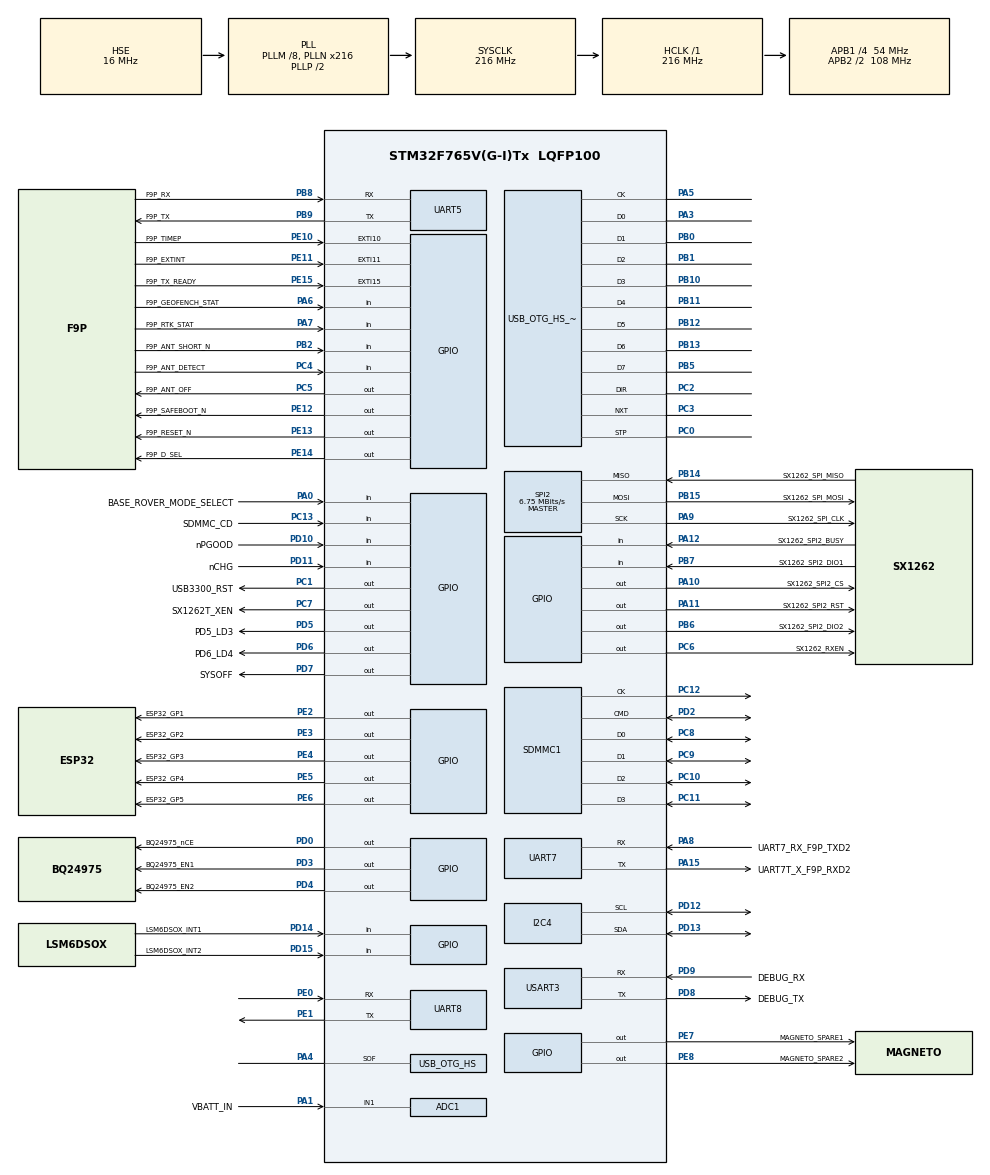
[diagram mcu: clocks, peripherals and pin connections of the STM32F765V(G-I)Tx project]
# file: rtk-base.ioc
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ADC1.Channel-1\#ChannelRegularConversion=ADC_CHANNEL_1
ADC1.NbrOfConversionFlag=1
ADC1.Rank-1\#ChannelRegularConversion=1
ADC1.SamplingTime-1\#ChannelRegularConversion=ADC_SAMPLETIME_3CYCLES
ADC1.master=1
CORTEX_M7.default_mode_Activation=1
FREERTOS.Tasks01=defaultTask,24,256,StartDefaultTask,Default,NULL,Dynamic,NULL,NULL
FREERTOS.configUSE_NEWLIB_REENTRANT=1
I2C4.Timing=0x20404768
Mcu.Family=STM32F7
Mcu.Name=STM32F765V(G-I)Tx
Mcu.Package=LQFP100
NVIC.OTG_HS_EP1_IN_IRQn=true\:5\:0\:false\:false\:true\:true\:true\:true\:true
NVIC.OTG_HS_EP1_OUT_IRQn=true\:5\:0\:false\:false\:true\:true\:true\:true\:true
NVIC.OTG_HS_IRQn=true\:5\:0\:false\:false\:true\:true\:true\:true\:true
NVIC.PriorityGroup=NVIC_PRIORITYGROUP_4
NVIC.TIM6_DAC_IRQn=true\:15\:0\:false\:false\:true\:false\:false\:true\:true
NVIC.TimeBase=TIM6_DAC_IRQn
NVIC.TimeBaseIP=TIM6
PA0/WKUP.GPIO_Label=BASE_ROVER_MODE_SELECT
PA0/WKUP.GPIO_PuPd=GPIO_PULLUP
PA0/WKUP.Signal=GPIO_Input
PA1.GPIO_Label=VBATT_IN
PA1.Signal=ADCx_IN1
PA10.GPIO_Label=SX1262_SPI2_CS
PA10.PinState=GPIO_PIN_SET
PA10.Signal=GPIO_Output
PA11.GPIO_Label=SX1262_SPI2_RST
PA11.Signal=GPIO_Output
PA12.GPIO_Label=SX1262_SPI2_BUSY
PA12.GPIO_PuPd=GPIO_PULLUP
PA12.Signal=GPIO_Input
PA13.Mode=Serial_Wire
PA13.Signal=SYS_JTMS-SWDIO
PA14.Mode=Serial_Wire
PA14.Signal=SYS_JTCK-SWCLK
PA15.GPIO_Label=UART7T_X_F9P_RXD2
PA15.Mode=Asynchronous
PA15.Signal=UART7_TX
PA3.Mode=Device_HS
PA3.Signal=USB_OTG_HS_ULPI_D0
PA4.Mode=Activate_SOF_FS
PA4.Signal=USB_OTG_HS_SOF
PA5.Mode=Device_HS
PA5.Signal=USB_OTG_HS_ULPI_CK
PA6.GPIO_Label=F9P_GEOFENCH_STAT
PA6.Signal=GPIO_Input
PA7.GPIO_Label=F9P_RTK_STAT
PA7.Signal=GPIO_Input
PA8.GPIO_Label=UART7_RX_F9P_TXD2
PA8.Mode=Asynchronous
PA8.Signal=UART7_RX
PA9.GPIO_Label=SX1262_SPI_CLK
PA9.Mode=Full_Duplex_Master
PA9.Signal=SPI2_SCK
PB0.Mode=Device_HS
PB0.Signal=USB_OTG_HS_ULPI_D1
PB1.Mode=Device_HS
PB1.Signal=USB_OTG_HS_ULPI_D2
PB10.Mode=Device_HS
PB10.Signal=USB_OTG_HS_ULPI_D3
PB11.Mode=Device_HS
PB11.Signal=USB_OTG_HS_ULPI_D4
PB12.Mode=Device_HS
PB12.Signal=USB_OTG_HS_ULPI_D5
PB13.Mode=Device_HS
PB13.Signal=USB_OTG_HS_ULPI_D6
PB14.GPIO_Label=SX1262_SPI_MISO
PB14.Mode=Full_Duplex_Master
PB14.Signal=SPI2_MISO
PB15.GPIO_Label=SX1262_SPI_MOSI
PB15.Mode=Full_Duplex_Master
PB15.Signal=SPI2_MOSI
PB2.GPIO_Label=F9P_ANT_SHORT_N
PB2.Signal=GPIO_Input
PB3.Signal=SYS_JTDO-SWO
PB5.Mode=Device_HS
PB5.Signal=USB_OTG_HS_ULPI_D7
PB6.GPIO_Label=SX1262_SPI2_DIO2
PB6.Signal=GPIO_Output
PB7.GPIO_Label=SX1262_SPI2_DIO1
PB7.Signal=GPIO_Input
PB8.GPIO_Label=F9P_RX
PB8.Mode=Asynchronous
PB8.Signal=UART5_RX
PB9.GPIO_Label=F9P_TX
PB9.Mode=Asynchronous
PB9.Signal=UART5_TX
PC0.Mode=Device_HS
PC0.Signal=USB_OTG_HS_ULPI_STP
PC1.GPIO_Label=USB3300_RST
PC1.GPIO_Speed=GPIO_SPEED_FREQ_HIGH
PC1.Signal=GPIO_Output
PC10.Mode=SD_4_bits_Wide_bus
PC10.Signal=SDMMC1_D2
PC11.Mode=SD_4_bits_Wide_bus
PC11.Signal=SDMMC1_D3
PC12.Mode=SD_4_bits_Wide_bus
PC12.Signal=SDMMC1_CK
PC13.GPIO_Label=SDMMC_CD
PC13.GPIO_PuPd=GPIO_PULLUP
PC13.Signal=GPIO_Input
PC2.Mode=Device_HS
PC2.Signal=USB_OTG_HS_ULPI_DIR
PC3.Mode=Device_HS
PC3.Signal=USB_OTG_HS_ULPI_NXT
PC4.GPIO_Label=F9P_ANT_DETECT
PC4.Signal=GPIO_Input
PC5.GPIO_Label=F9P_ANT_OFF
PC5.Signal=GPIO_Output
PC6.GPIO_Label=SX1262_RXEN
PC6.Signal=GPIO_Output
PC7.GPIO_Label=SX1262T_XEN
PC7.Signal=GPIO_Output
PC8.Mode=SD_4_bits_Wide_bus
PC8.Signal=SDMMC1_D0
PC9.Mode=SD_4_bits_Wide_bus
PC9.Signal=SDMMC1_D1
PD0.GPIO_Label=BQ24975_nCE
PD0.Signal=GPIO_Output
PD10.GPIO_Label=nPGOOD
PD10.Signal=GPIO_Input
PD11.GPIO_Label=nCHG
PD11.Signal=GPIO_Input
PD12.Mode=I2C
PD12.Signal=I2C4_SCL
PD13.Mode=I2C
PD13.Signal=I2C4_SDA
PD14.GPIO_Label=LSM6DSOX_INT1
PD14.Signal=GPIO_Input
PD15.GPIO_Label=LSM6DSOX_INT2
PD15.Signal=GPIO_Input
PD2.Mode=SD_4_bits_Wide_bus
PD2.Signal=SDMMC1_CMD
PD3.GPIO_Label=BQ24975_EN1
PD3.PinState=GPIO_PIN_SET
PD3.Signal=GPIO_Output
PD4.GPIO_Label=BQ24975_EN2
PD4.PinState=GPIO_PIN_RESET
PD4.Signal=GPIO_Output
PD5.GPIO_Label=PD5_LD3
PD5.GPIO_ModeDefaultOutputPP=GPIO_MODE_OUTPUT_OD
PD5.GPIO_PuPd=GPIO_NOPULL
PD5.Signal=GPIO_Output
PD6.GPIO_Label=PD6_LD4
PD6.GPIO_ModeDefaultOutputPP=GPIO_MODE_OUTPUT_OD
PD6.GPIO_PuPd=GPIO_NOPULL
PD6.Signal=GPIO_Output
PD7.GPIO_Label=SYSOFF
PD7.Signal=GPIO_Output
PD8.GPIO_Label=DEBUG_TX
PD8.Mode=Asynchronous
PD8.Signal=USART3_TX
PD9.GPIO_Label=DEBUG_RX
PD9.Mode=Asynchronous
PD9.Signal=USART3_RX
PE0.Mode=Asynchronous
PE0.Signal=UART8_RX
PE1.Mode=Asynchronous
PE1.Signal=UART8_TX
PE10.GPIO_Label=F9P_TIMEP
PE10.Signal=GPXTI10
PE11.GPIO_Label=F9P_EXTINT
PE11.Signal=GPXTI11
PE12.GPIO_Label=F9P_SAFEBOOT_N
PE12.PinState=GPIO_PIN_SET
PE12.Signal=GPIO_Output
PE13.GPIO_Label=F9P_RESET_N
PE13.PinState=GPIO_PIN_SET
PE13.Signal=GPIO_Output
PE14.GPIO_Label=F9P_D_SEL
PE14.PinState=GPIO_PIN_SET
PE14.Signal=GPIO_Output
PE15.GPIO_Label=F9P_TX_READY
PE15.Signal=GPXTI15
PE2.GPIO_Label=ESP32_GP1
PE2.Signal=GPIO_Output
PE3.GPIO_Label=ESP32_GP2
PE3.Signal=GPIO_Output
PE4.GPIO_Label=ESP32_GP3
PE4.Signal=GPIO_Output
PE5.GPIO_Label=ESP32_GP4
PE5.Signal=GPIO_Output
PE6.GPIO_Label=ESP32_GP5
PE6.Signal=GPIO_Output
PE7.GPIO_Label=MAGNETO_SPARE1
PE7.Signal=GPIO_Output
PE8.GPIO_Label=MAGNETO_SPARE2
PE8.Signal=GPIO_Output
PH0/OSC_IN.Mode=HSE-External-Oscillator
PH0/OSC_IN.Signal=RCC_OSC_IN
PH1/OSC_OUT.Mode=HSE-External-Oscillator
PH1/OSC_OUT.Signal=RCC_OSC_OUT
ProjectManager.HeapSize=0x200
ProjectManager.StackSize=0x400
ProjectManager.TargetToolchain=STM32CubeIDE
RCC.AHBFreq_Value=216000000
RCC.APB1CLKDivider=RCC_HCLK_DIV4
RCC.APB1Freq_Value=54000000
RCC.APB1TimFreq_Value=108000000
RCC.APB2CLKDivider=RCC_HCLK_DIV2
RCC.APB2Freq_Value=108000000
RCC.APB2TimFreq_Value=216000000
RCC.CortexFreq_Value=216000000
RCC.HCLKFreq_Value=216000000
RCC.HSE_VALUE=16000000
RCC.HSI_VALUE=16000000
RCC.LSE_VALUE=32768
RCC.PLLM=8
RCC.PLLN=216
RCC.PLLQ=9
RCC.PLLSourceVirtual=RCC_PLLSOURCE_HSE
RCC.SDMMCClockSelection=RCC_SDMMC1CLKSOURCE_CLK48
RCC.SYSCLKFreq_VALUE=216000000
RCC.SYSCLKSource=RCC_SYSCLKSOURCE_PLLCLK
RCC.USBFreq_Value=48000000
RCC.VCOOutputFreq_Value=432000000
SH.ADCx_IN1.0=ADC1_IN1,IN1
SPI2.BaudRatePrescaler=SPI_BAUDRATEPRESCALER_8
SPI2.CalculateBaudRate=6.75 MBits/s
SPI2.DataSize=SPI_DATASIZE_8BIT
SPI2.Direction=SPI_DIRECTION_2LINES
SPI2.Mode=SPI_MODE_MASTER
SPI2.VirtualType=VM_MASTER
USART3.VirtualMode-Asynchronous=VM_ASYNC
USB_OTG_HS.VirtualMode-Device_HS=Device_HS
VP_FREERTOS_VS_CMSIS_V2.Mode=CMSIS_V2
VP_SYS_VS_tim6.Mode=TIM6
board=custom

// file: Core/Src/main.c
/* USER CODE BEGIN Header */
/**
  ******************************************************************************
  * @file           : main.c
  * @brief          : Main program body
  ******************************************************************************
  * @attention
  *
  * Copyright (c) 2026 STMicroelectronics.
  * All rights reserved.
  *
  * This software is licensed under terms that can be found in the LICENSE file
  * in the root directory of this software component.
  * If no LICENSE file comes with this software, it is provided AS-IS.
  *
  ******************************************************************************
  */
/* USER CODE END Header */
#include "main.h"
#include "cmsis_os.h"

/* USER CODE BEGIN Includes */
#include "task_battery.h"
/* USER CODE END Includes */

ADC_HandleTypeDef hadc1;

I2C_HandleTypeDef hi2c4;

SD_HandleTypeDef hsd1;

SPI_HandleTypeDef hspi2;

UART_HandleTypeDef huart5;
UART_HandleTypeDef huart7;
UART_HandleTypeDef huart8;
UART_HandleTypeDef huart3;

PCD_HandleTypeDef hpcd_USB_OTG_HS;

/* Definitions for defaultTask */
osThreadId_t defaultTaskHandle;
const osThreadAttr_t defaultTask_attributes = {
  .name = "defaultTask",
  .stack_size = 256 * 4,
  .priority = (osPriority_t) osPriorityNormal,
};
/* USER CODE BEGIN PV */
osThreadId_t batteryTaskHandle;
const osThreadAttr_t batteryTask_attributes = {
	.name       = "batteryTask",
	.stack_size = 128 * 4,
	.priority   = (osPriority_t)osPriorityBelowNormal,
};
/* USER CODE END PV */

void SystemClock_Config(void);
static void MPU_Config(void);
static void MX_GPIO_Init(void);
static void MX_USART3_UART_Init(void);
static void MX_I2C4_Init(void);
static void MX_SDMMC1_SD_Init(void);
static void MX_SPI2_Init(void);
static void MX_UART5_Init(void);
static void MX_UART8_Init(void);
static void MX_USB_OTG_HS_PCD_Init(void);
static void MX_ADC1_Init(void);
static void MX_UART7_Init(void);
void StartDefaultTask(void *argument);

int main(void)
{

  /* MPU Configuration--------------------------------------------------------*/
  MPU_Config();

  /* MCU Configuration--------------------------------------------------------*/

  /* Reset of all peripherals, Initializes the Flash interface and the Systick. */
  HAL_Init();

  /* Configure the system clock */
  SystemClock_Config();

  /* Initialize all configured peripherals */
  MX_GPIO_Init();
  MX_USART3_UART_Init();
  MX_I2C4_Init();
  MX_SDMMC1_SD_Init();
  MX_SPI2_Init();
  MX_UART5_Init();
  MX_UART8_Init();
  MX_USB_OTG_HS_PCD_Init();
  MX_ADC1_Init();
  MX_UART7_Init();

  /* Init scheduler */
  osKernelInitialize();

  /* Create the thread(s) */
  /* creation of defaultTask */
  defaultTaskHandle = osThreadNew(StartDefaultTask, NULL, &defaultTask_attributes);

  /* USER CODE BEGIN RTOS_THREADS */
  batteryTaskHandle = osThreadNew(task_battery, NULL, &batteryTask_attributes);
  /* USER CODE END RTOS_THREADS */

  /* Start scheduler */
  osKernelStart();

  /* We should never get here as control is now taken by the scheduler */

  /* Infinite loop */
  while (1)
  {

  }
}

void SystemClock_Config(void)
{
  RCC_OscInitTypeDef RCC_OscInitStruct = {0};
  RCC_ClkInitTypeDef RCC_ClkInitStruct = {0};

  /** Configure the main internal regulator output voltage
  */
  __HAL_RCC_PWR_CLK_ENABLE();
  __HAL_PWR_VOLTAGESCALING_CONFIG(PWR_REGULATOR_VOLTAGE_SCALE1);

  /** Initializes the RCC Oscillators according to the specified parameters
  * in the RCC_OscInitTypeDef structure.
  */
  RCC_OscInitStruct.OscillatorType = RCC_OSCILLATORTYPE_HSE;
  RCC_OscInitStruct.HSEState = RCC_HSE_ON;
  RCC_OscInitStruct.PLL.PLLState = RCC_PLL_ON;
  RCC_OscInitStruct.PLL.PLLSource = RCC_PLLSOURCE_HSE;
  RCC_OscInitStruct.PLL.PLLM = 8;
  RCC_OscInitStruct.PLL.PLLN = 216;
  RCC_OscInitStruct.PLL.PLLP = RCC_PLLP_DIV2;
  RCC_OscInitStruct.PLL.PLLQ = 9;
  RCC_OscInitStruct.PLL.PLLR = 2;
  if (HAL_RCC_OscConfig(&RCC_OscInitStruct) != HAL_OK)
  {
    Error_Handler();
  }

  /** Activate the Over-Drive mode
  */
  if (HAL_PWREx_EnableOverDrive() != HAL_OK)
  {
    Error_Handler();
  }

  /** Initializes the CPU, AHB and APB buses clocks
  */
  RCC_ClkInitStruct.ClockType = RCC_CLOCKTYPE_HCLK|RCC_CLOCKTYPE_SYSCLK
                              |RCC_CLOCKTYPE_PCLK1|RCC_CLOCKTYPE_PCLK2;
  RCC_ClkInitStruct.SYSCLKSource = RCC_SYSCLKSOURCE_PLLCLK;
  RCC_ClkInitStruct.AHBCLKDivider = RCC_SYSCLK_DIV1;
  RCC_ClkInitStruct.APB1CLKDivider = RCC_HCLK_DIV4;
  RCC_ClkInitStruct.APB2CLKDivider = RCC_HCLK_DIV2;

  if (HAL_RCC_ClockConfig(&RCC_ClkInitStruct, FLASH_LATENCY_7) != HAL_OK)
  {
    Error_Handler();
  }
}

static void MX_ADC1_Init(void)
{

  ADC_ChannelConfTypeDef sConfig = {0};

  /** Configure the global features of the ADC (Clock, Resolution, Data Alignment and number of conversion)
  */
  hadc1.Instance = ADC1;
  hadc1.Init.ClockPrescaler = ADC_CLOCK_SYNC_PCLK_DIV4;
  hadc1.Init.Resolution = ADC_RESOLUTION_12B;
  hadc1.Init.ScanConvMode = ADC_SCAN_DISABLE;
  hadc1.Init.ContinuousConvMode = DISABLE;
  hadc1.Init.DiscontinuousConvMode = DISABLE;
  hadc1.Init.ExternalTrigConvEdge = ADC_EXTERNALTRIGCONVEDGE_NONE;
  hadc1.Init.ExternalTrigConv = ADC_SOFTWARE_START;
  hadc1.Init.DataAlign = ADC_DATAALIGN_RIGHT;
  hadc1.Init.NbrOfConversion = 1;
  hadc1.Init.DMAContinuousRequests = DISABLE;
  hadc1.Init.EOCSelection = ADC_EOC_SINGLE_CONV;
  if (HAL_ADC_Init(&hadc1) != HAL_OK)
  {
    Error_Handler();
  }

  /** Configure for the selected ADC regular channel its corresponding rank in the sequencer and its sample time.
  */
  sConfig.Channel = ADC_CHANNEL_1;
  sConfig.Rank = ADC_REGULAR_RANK_1;
  sConfig.SamplingTime = ADC_SAMPLETIME_3CYCLES;
  if (HAL_ADC_ConfigChannel(&hadc1, &sConfig) != HAL_OK)
  {
    Error_Handler();
  }

}

static void MX_I2C4_Init(void)
{

  hi2c4.Instance = I2C4;
  hi2c4.Init.Timing = 0x20404768;
  hi2c4.Init.OwnAddress1 = 0;
  hi2c4.Init.AddressingMode = I2C_ADDRESSINGMODE_7BIT;
  hi2c4.Init.DualAddressMode = I2C_DUALADDRESS_DISABLE;
  hi2c4.Init.OwnAddress2 = 0;
  hi2c4.Init.OwnAddress2Masks = I2C_OA2_NOMASK;
  hi2c4.Init.GeneralCallMode = I2C_GENERALCALL_DISABLE;
  hi2c4.Init.NoStretchMode = I2C_NOSTRETCH_DISABLE;
  if (HAL_I2C_Init(&hi2c4) != HAL_OK)
  {
    Error_Handler();
  }

  /** Configure Analogue filter
  */
  if (HAL_I2CEx_ConfigAnalogFilter(&hi2c4, I2C_ANALOGFILTER_ENABLE) != HAL_OK)
  {
    Error_Handler();
  }

  /** Configure Digital filter
  */
  if (HAL_I2CEx_ConfigDigitalFilter(&hi2c4, 0) != HAL_OK)
  {
    Error_Handler();
  }

}

static void MX_SDMMC1_SD_Init(void)
{

  hsd1.Instance = SDMMC1;
  hsd1.Init.ClockEdge = SDMMC_CLOCK_EDGE_RISING;
  hsd1.Init.ClockBypass = SDMMC_CLOCK_BYPASS_DISABLE;
  hsd1.Init.ClockPowerSave = SDMMC_CLOCK_POWER_SAVE_DISABLE;
  hsd1.Init.BusWide = SDMMC_BUS_WIDE_1B;
  hsd1.Init.HardwareFlowControl = SDMMC_HARDWARE_FLOW_CONTROL_DISABLE;
  hsd1.Init.ClockDiv = 0;
  if (HAL_SD_Init(&hsd1) != HAL_OK)
  {
    Error_Handler();
  }
  if (HAL_SD_ConfigWideBusOperation(&hsd1, SDMMC_BUS_WIDE_4B) != HAL_OK)
  {
    Error_Handler();
  }

}

static void MX_SPI2_Init(void)
{

  /* SPI2 parameter configuration*/
  hspi2.Instance = SPI2;
  hspi2.Init.Mode = SPI_MODE_MASTER;
  hspi2.Init.Direction = SPI_DIRECTION_2LINES;
  hspi2.Init.DataSize = SPI_DATASIZE_8BIT;
  hspi2.Init.CLKPolarity = SPI_POLARITY_LOW;
  hspi2.Init.CLKPhase = SPI_PHASE_1EDGE;
  hspi2.Init.NSS = SPI_NSS_SOFT;
  hspi2.Init.BaudRatePrescaler = SPI_BAUDRATEPRESCALER_8;
  hspi2.Init.FirstBit = SPI_FIRSTBIT_MSB;
  hspi2.Init.TIMode = SPI_TIMODE_DISABLE;
  hspi2.Init.CRCCalculation = SPI_CRCCALCULATION_DISABLE;
  hspi2.Init.CRCPolynomial = 7;
  hspi2.Init.CRCLength = SPI_CRC_LENGTH_DATASIZE;
  hspi2.Init.NSSPMode = SPI_NSS_PULSE_ENABLE;
  if (HAL_SPI_Init(&hspi2) != HAL_OK)
  {
    Error_Handler();
  }

}

static void MX_UART5_Init(void)
{

  huart5.Instance = UART5;
  huart5.Init.BaudRate = 115200;
  huart5.Init.WordLength = UART_WORDLENGTH_8B;
  huart5.Init.StopBits = UART_STOPBITS_1;
  huart5.Init.Parity = UART_PARITY_NONE;
  huart5.Init.Mode = UART_MODE_TX_RX;
  huart5.Init.HwFlowCtl = UART_HWCONTROL_NONE;
  huart5.Init.OverSampling = UART_OVERSAMPLING_16;
  huart5.Init.OneBitSampling = UART_ONE_BIT_SAMPLE_DISABLE;
  huart5.AdvancedInit.AdvFeatureInit = UART_ADVFEATURE_NO_INIT;
  if (HAL_UART_Init(&huart5) != HAL_OK)
  {
    Error_Handler();
  }

}

static void MX_UART7_Init(void)
{

  huart7.Instance = UART7;
  huart7.Init.BaudRate = 115200;
  huart7.Init.WordLength = UART_WORDLENGTH_8B;
  huart7.Init.StopBits = UART_STOPBITS_1;
  huart7.Init.Parity = UART_PARITY_NONE;
  huart7.Init.Mode = UART_MODE_TX_RX;
  huart7.Init.HwFlowCtl = UART_HWCONTROL_NONE;
  huart7.Init.OverSampling = UART_OVERSAMPLING_16;
  huart7.Init.OneBitSampling = UART_ONE_BIT_SAMPLE_DISABLE;
  huart7.AdvancedInit.AdvFeatureInit = UART_ADVFEATURE_NO_INIT;
  if (HAL_UART_Init(&huart7) != HAL_OK)
  {
    Error_Handler();
  }

}

static void MX_UART8_Init(void)
{

  huart8.Instance = UART8;
  huart8.Init.BaudRate = 115200;
  huart8.Init.WordLength = UART_WORDLENGTH_8B;
  huart8.Init.StopBits = UART_STOPBITS_1;
  huart8.Init.Parity = UART_PARITY_NONE;
  huart8.Init.Mode = UART_MODE_TX_RX;
  huart8.Init.HwFlowCtl = UART_HWCONTROL_NONE;
  huart8.Init.OverSampling = UART_OVERSAMPLING_16;
  huart8.Init.OneBitSampling = UART_ONE_BIT_SAMPLE_DISABLE;
  huart8.AdvancedInit.AdvFeatureInit = UART_ADVFEATURE_NO_INIT;
  if (HAL_UART_Init(&huart8) != HAL_OK)
  {
    Error_Handler();
  }

}

static void MX_USART3_UART_Init(void)
{

  huart3.Instance = USART3;
  huart3.Init.BaudRate = 115200;
  huart3.Init.WordLength = UART_WORDLENGTH_8B;
  huart3.Init.StopBits = UART_STOPBITS_1;
  huart3.Init.Parity = UART_PARITY_NONE;
  huart3.Init.Mode = UART_MODE_TX_RX;
  huart3.Init.HwFlowCtl = UART_HWCONTROL_NONE;
  huart3.Init.OverSampling = UART_OVERSAMPLING_16;
  huart3.Init.OneBitSampling = UART_ONE_BIT_SAMPLE_DISABLE;
  huart3.AdvancedInit.AdvFeatureInit = UART_ADVFEATURE_NO_INIT;
  if (HAL_UART_Init(&huart3) != HAL_OK)
  {
    Error_Handler();
  }

}

static void MX_USB_OTG_HS_PCD_Init(void)
{

  hpcd_USB_OTG_HS.Instance = USB_OTG_HS;
  hpcd_USB_OTG_HS.Init.dev_endpoints = 9;
  hpcd_USB_OTG_HS.Init.speed = PCD_SPEED_HIGH;
  hpcd_USB_OTG_HS.Init.dma_enable = DISABLE;
  hpcd_USB_OTG_HS.Init.phy_itface = USB_OTG_ULPI_PHY;
  hpcd_USB_OTG_HS.Init.Sof_enable = ENABLE;
  hpcd_USB_OTG_HS.Init.low_power_enable = DISABLE;
  hpcd_USB_OTG_HS.Init.lpm_enable = DISABLE;
  hpcd_USB_OTG_HS.Init.vbus_sensing_enable = DISABLE;
  hpcd_USB_OTG_HS.Init.use_dedicated_ep1 = DISABLE;
  hpcd_USB_OTG_HS.Init.use_external_vbus = DISABLE;
  if (HAL_PCD_Init(&hpcd_USB_OTG_HS) != HAL_OK)
  {
    Error_Handler();
  }

}

static void MX_GPIO_Init(void)
{
  GPIO_InitTypeDef GPIO_InitStruct = {0};

  /* GPIO Ports Clock Enable */
  __HAL_RCC_GPIOE_CLK_ENABLE();
  __HAL_RCC_GPIOC_CLK_ENABLE();
  __HAL_RCC_GPIOH_CLK_ENABLE();
  __HAL_RCC_GPIOA_CLK_ENABLE();
  __HAL_RCC_GPIOB_CLK_ENABLE();
  __HAL_RCC_GPIOD_CLK_ENABLE();

  /*Configure GPIO pin Output Level */
  HAL_GPIO_WritePin(GPIOE, ESP32_GP1_Pin|ESP32_GP2_Pin|ESP32_GP3_Pin|ESP32_GP4_Pin
                          |ESP32_GP5_Pin|MAGNETO_SPARE1_Pin|MAGNETO_SPARE2_Pin, GPIO_PIN_RESET);

  /*Configure GPIO pin Output Level */
  HAL_GPIO_WritePin(GPIOC, USB3300_RST_Pin|F9P_ANT_OFF_Pin|SX1262_RXEN_Pin|SX1262T_XEN_Pin, GPIO_PIN_RESET);

  /*Configure GPIO pin Output Level */
  HAL_GPIO_WritePin(GPIOE, F9P_SAFEBOOT_N_Pin|F9P_RESET_N_Pin|F9P_D_SEL_Pin, GPIO_PIN_SET);

  /*Configure GPIO pin Output Level */
  HAL_GPIO_WritePin(SX1262_SPI2_CS_GPIO_Port, SX1262_SPI2_CS_Pin, GPIO_PIN_SET);

  /*Configure GPIO pin Output Level */
  HAL_GPIO_WritePin(SX1262_SPI2_RST_GPIO_Port, SX1262_SPI2_RST_Pin, GPIO_PIN_RESET);

  /*Configure GPIO pin Output Level */
  HAL_GPIO_WritePin(GPIOD, BQ24975_nCE_Pin|BQ24975_EN2_Pin|PD5_LD3_Pin|PD6_LD4_Pin
                          |SYSOFF_Pin, GPIO_PIN_RESET);

  /*Configure GPIO pin Output Level */
  HAL_GPIO_WritePin(BQ24975_EN1_GPIO_Port, BQ24975_EN1_Pin, GPIO_PIN_SET);

  /*Configure GPIO pin Output Level */
  HAL_GPIO_WritePin(SX1262_SPI2_DIO2_GPIO_Port, SX1262_SPI2_DIO2_Pin, GPIO_PIN_RESET);

  /*Configure GPIO pins : ESP32_GP1_Pin ESP32_GP2_Pin ESP32_GP3_Pin ESP32_GP4_Pin
                           ESP32_GP5_Pin MAGNETO_SPARE1_Pin MAGNETO_SPARE2_Pin F9P_SAFEBOOT_N_Pin
                           F9P_RESET_N_Pin F9P_D_SEL_Pin */
  GPIO_InitStruct.Pin = ESP32_GP1_Pin|ESP32_GP2_Pin|ESP32_GP3_Pin|ESP32_GP4_Pin
                          |ESP32_GP5_Pin|MAGNETO_SPARE1_Pin|MAGNETO_SPARE2_Pin|F9P_SAFEBOOT_N_Pin
                          |F9P_RESET_N_Pin|F9P_D_SEL_Pin;
  GPIO_InitStruct.Mode = GPIO_MODE_OUTPUT_PP;
  GPIO_InitStruct.Pull = GPIO_NOPULL;
  GPIO_InitStruct.Speed = GPIO_SPEED_FREQ_LOW;
  HAL_GPIO_Init(GPIOE, &GPIO_InitStruct);

  /*Configure GPIO pin : SDMMC_CD_Pin */
  GPIO_InitStruct.Pin = SDMMC_CD_Pin;
  GPIO_InitStruct.Mode = GPIO_MODE_INPUT;
  GPIO_InitStruct.Pull = GPIO_PULLUP;
  HAL_GPIO_Init(SDMMC_CD_GPIO_Port, &GPIO_InitStruct);

  /*Configure GPIO pin : USB3300_RST_Pin */
  GPIO_InitStruct.Pin = USB3300_RST_Pin;
  GPIO_InitStruct.Mode = GPIO_MODE_OUTPUT_PP;
  GPIO_InitStruct.Pull = GPIO_NOPULL;
  GPIO_InitStruct.Speed = GPIO_SPEED_FREQ_HIGH;
  HAL_GPIO_Init(USB3300_RST_GPIO_Port, &GPIO_InitStruct);

  /*Configure GPIO pins : BASE_ROVER_MODE_SELECT_Pin SX1262_SPI2_BUSY_Pin */
  GPIO_InitStruct.Pin = BASE_ROVER_MODE_SELECT_Pin|SX1262_SPI2_BUSY_Pin;
  GPIO_InitStruct.Mode = GPIO_MODE_INPUT;
  GPIO_InitStruct.Pull = GPIO_PULLUP;
  HAL_GPIO_Init(GPIOA, &GPIO_InitStruct);

  /*Configure GPIO pins : F9P_GEOFENCH_STAT_Pin F9P_RTK_STAT_Pin */
  GPIO_InitStruct.Pin = F9P_GEOFENCH_STAT_Pin|F9P_RTK_STAT_Pin;
  GPIO_InitStruct.Mode = GPIO_MODE_INPUT;
  GPIO_InitStruct.Pull = GPIO_NOPULL;
  HAL_GPIO_Init(GPIOA, &GPIO_InitStruct);

  /*Configure GPIO pin : F9P_ANT_DETECT_Pin */
  GPIO_InitStruct.Pin = F9P_ANT_DETECT_Pin;
  GPIO_InitStruct.Mode = GPIO_MODE_INPUT;
  GPIO_InitStruct.Pull = GPIO_NOPULL;
  HAL_GPIO_Init(F9P_ANT_DETECT_GPIO_Port, &GPIO_InitStruct);

  /*Configure GPIO pins : F9P_ANT_OFF_Pin SX1262_RXEN_Pin SX1262T_XEN_Pin */
  GPIO_InitStruct.Pin = F9P_ANT_OFF_Pin|SX1262_RXEN_Pin|SX1262T_XEN_Pin;
  GPIO_InitStruct.Mode = GPIO_MODE_OUTPUT_PP;
  GPIO_InitStruct.Pull = GPIO_NOPULL;
  GPIO_InitStruct.Speed = GPIO_SPEED_FREQ_LOW;
  HAL_GPIO_Init(GPIOC, &GPIO_InitStruct);

  /*Configure GPIO pins : F9P_ANT_SHORT_N_Pin SX1262_SPI2_DIO1_Pin */
  GPIO_InitStruct.Pin = F9P_ANT_SHORT_N_Pin|SX1262_SPI2_DIO1_Pin;
  GPIO_InitStruct.Mode = GPIO_MODE_INPUT;
  GPIO_InitStruct.Pull = GPIO_NOPULL;
  HAL_GPIO_Init(GPIOB, &GPIO_InitStruct);

  /*Configure GPIO pins : F9P_TIMEP_Pin F9P_EXTINT_Pin F9P_TX_READY_Pin */
  GPIO_InitStruct.Pin = F9P_TIMEP_Pin|F9P_EXTINT_Pin|F9P_TX_READY_Pin;
  GPIO_InitStruct.Mode = GPIO_MODE_IT_RISING;
  GPIO_InitStruct.Pull = GPIO_NOPULL;
  HAL_GPIO_Init(GPIOE, &GPIO_InitStruct);

  /*Configure GPIO pins : nPGOOD_Pin nCHG_Pin LSM6DSOX_INT1_Pin LSM6DSOX_INT2_Pin */
  GPIO_InitStruct.Pin = nPGOOD_Pin|nCHG_Pin|LSM6DSOX_INT1_Pin|LSM6DSOX_INT2_Pin;
  GPIO_InitStruct.Mode = GPIO_MODE_INPUT;
  GPIO_InitStruct.Pull = GPIO_NOPULL;
  HAL_GPIO_Init(GPIOD, &GPIO_InitStruct);

  /*Configure GPIO pins : SX1262_SPI2_CS_Pin SX1262_SPI2_RST_Pin */
  GPIO_InitStruct.Pin = SX1262_SPI2_CS_Pin|SX1262_SPI2_RST_Pin;
  GPIO_InitStruct.Mode = GPIO_MODE_OUTPUT_PP;
  GPIO_InitStruct.Pull = GPIO_NOPULL;
  GPIO_InitStruct.Speed = GPIO_SPEED_FREQ_LOW;
  HAL_GPIO_Init(GPIOA, &GPIO_InitStruct);

  /*Configure GPIO pins : BQ24975_nCE_Pin BQ24975_EN1_Pin BQ24975_EN2_Pin SYSOFF_Pin */
  GPIO_InitStruct.Pin = BQ24975_nCE_Pin|BQ24975_EN1_Pin|BQ24975_EN2_Pin|SYSOFF_Pin;
  GPIO_InitStruct.Mode = GPIO_MODE_OUTPUT_PP;
  GPIO_InitStruct.Pull = GPIO_NOPULL;
  GPIO_InitStruct.Speed = GPIO_SPEED_FREQ_LOW;
  HAL_GPIO_Init(GPIOD, &GPIO_InitStruct);

  /*Configure GPIO pins : PD5_LD3_Pin PD6_LD4_Pin */
  GPIO_InitStruct.Pin = PD5_LD3_Pin|PD6_LD4_Pin;
  GPIO_InitStruct.Mode = GPIO_MODE_OUTPUT_OD;
  GPIO_InitStruct.Pull = GPIO_NOPULL;
  GPIO_InitStruct.Speed = GPIO_SPEED_FREQ_LOW;
  HAL_GPIO_Init(GPIOD, &GPIO_InitStruct);

  /*Configure GPIO pin : SX1262_SPI2_DIO2_Pin */
  GPIO_InitStruct.Pin = SX1262_SPI2_DIO2_Pin;
  GPIO_InitStruct.Mode = GPIO_MODE_OUTPUT_PP;
  GPIO_InitStruct.Pull = GPIO_NOPULL;
  GPIO_InitStruct.Speed = GPIO_SPEED_FREQ_LOW;
  HAL_GPIO_Init(SX1262_SPI2_DIO2_GPIO_Port, &GPIO_InitStruct);

}

void StartDefaultTask(void *argument)
{
  for(;;)
  {
    osDelay(1);
  }
}

 /* MPU Configuration */

void MPU_Config(void)
{
  MPU_Region_InitTypeDef MPU_InitStruct = {0};

  /* Disables the MPU */
  HAL_MPU_Disable();

  /** Initializes and configures the Region and the memory to be protected
  */
  MPU_InitStruct.Enable = MPU_REGION_ENABLE;
  MPU_InitStruct.Number = MPU_REGION_NUMBER0;
  MPU_InitStruct.BaseAddress = 0x0;
  MPU_InitStruct.Size = MPU_REGION_SIZE_4GB;
  MPU_InitStruct.SubRegionDisable = 0x87;
  MPU_InitStruct.TypeExtField = MPU_TEX_LEVEL0;
  MPU_InitStruct.AccessPermission = MPU_REGION_NO_ACCESS;
  MPU_InitStruct.DisableExec = MPU_INSTRUCTION_ACCESS_DISABLE;
  MPU_InitStruct.IsShareable = MPU_ACCESS_SHAREABLE;
  MPU_InitStruct.IsCacheable = MPU_ACCESS_NOT_CACHEABLE;
  MPU_InitStruct.IsBufferable = MPU_ACCESS_NOT_BUFFERABLE;

  HAL_MPU_ConfigRegion(&MPU_InitStruct);
  /* Enables the MPU */
  HAL_MPU_Enable(MPU_PRIVILEGED_DEFAULT);

}

void HAL_TIM_PeriodElapsedCallback(TIM_HandleTypeDef *htim)
{
  if (htim->Instance == TIM6)
  {
    HAL_IncTick();
  }
}

void Error_Handler(void)
{
  __disable_irq();
  while (1)
  {
  }
}
